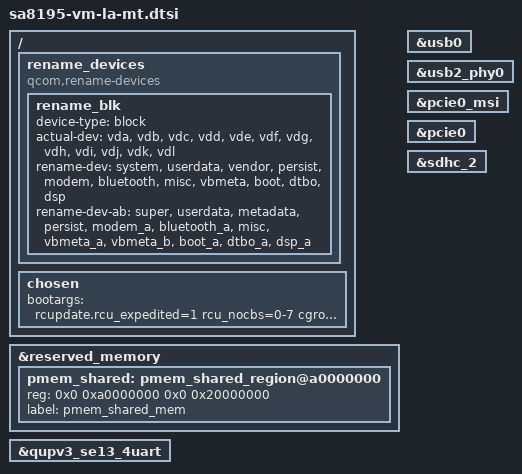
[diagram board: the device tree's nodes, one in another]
&reserved_memory {
	pmem_shared: pmem_shared_region@a0000000 {
		reg = <0x0 0xa0000000 0x0 0x20000000>;
		label = "pmem_shared_mem";
	};
};

#include "display/quin-vm-display-la.dtsi"

/ {
	rename_devices: rename_devices {
		compatible = "qcom,rename-devices";
		rename_blk: rename_blk {
			device-type = "block";
			actual-dev = "vda", "vdb", "vdc",
					"vdd", "vde", "vdf",
					"vdg", "vdh", "vdi",
					"vdj", "vdk", "vdl";
			rename-dev = "system", "userdata", "vendor",
					"persist", "modem", "bluetooth",
					"misc", "vbmeta", "boot", "dtbo",
					"dsp";
			rename-dev-ab = "super", "userdata", "metadata",
					"persist", "modem_a", "bluetooth_a",
					"misc", "vbmeta_a", "vbmeta_b",
					"boot_a", "dtbo_a", "dsp_a";
		};
	};

	/delete-node/ cpus;

	chosen {
		bootargs = "rcupdate.rcu_expedited=1 rcu_nocbs=0-7 cgroup.memory=nokmem,nosocket androidboot.usbcontroller=a600000.dwc3 androidboot.fstab_suffix=gen3.qcom";
	};
};

&usb0 {
	status = "ok";
};

&usb2_phy0 {
	status = "ok";
};

&qupv3_se13_4uart {
	status = "ok";
};

&pcie0_msi {
	status = "ok";
};

&pcie0 {
	status = "ok";
};

&sdhc_2 {
	status = "ok";
};

